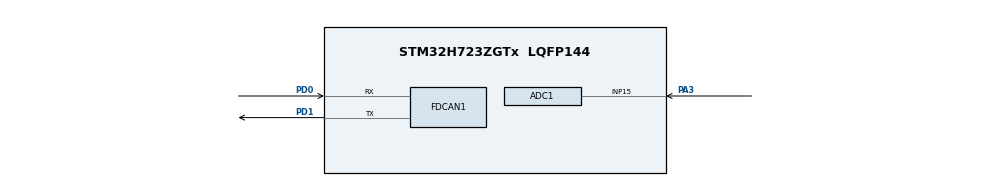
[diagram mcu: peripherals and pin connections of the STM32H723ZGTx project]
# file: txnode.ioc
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ADC1.Channel-0\#ChannelRegularConversion=ADC_CHANNEL_15
ADC1.ContinuousConvMode=DISABLE
ADC1.ConversionDataManagement=ADC_CONVERSIONDATA_DMA_CIRCULAR
ADC1.ExternalTrigConv=ADC_EXTERNALTRIG_T6_TRGO
ADC1.NbrOfConversionFlag=1
ADC1.OffsetNumber-0\#ChannelRegularConversion=ADC_OFFSET_NONE
ADC1.OffsetSignedSaturation-0\#ChannelRegularConversion=DISABLE
ADC1.Rank-0\#ChannelRegularConversion=1
ADC1.SamplingTime-0\#ChannelRegularConversion=ADC_SAMPLETIME_387CYCLES_5
ADC1.master=1
CORTEX_M7.default_mode_Activation=1
Dma.ADC1.0.Direction=DMA_PERIPH_TO_MEMORY
Dma.ADC1.0.EventEnable=DISABLE
Dma.ADC1.0.FIFOMode=DMA_FIFOMODE_DISABLE
Dma.ADC1.0.Instance=DMA1_Stream0
Dma.ADC1.0.MemDataAlignment=DMA_MDATAALIGN_HALFWORD
Dma.ADC1.0.MemInc=DMA_MINC_ENABLE
Dma.ADC1.0.Mode=DMA_CIRCULAR
Dma.ADC1.0.PeriphDataAlignment=DMA_PDATAALIGN_HALFWORD
Dma.ADC1.0.PeriphInc=DMA_PINC_DISABLE
Dma.ADC1.0.Polarity=HAL_DMAMUX_REQ_GEN_RISING
Dma.ADC1.0.Priority=DMA_PRIORITY_LOW
Dma.ADC1.0.RequestNumber=1
Dma.ADC1.0.SignalID=NONE
Dma.ADC1.0.SyncEnable=DISABLE
Dma.ADC1.0.SyncPolarity=HAL_DMAMUX_SYNC_NO_EVENT
Dma.ADC1.0.SyncRequestNumber=1
Dma.ADC1.0.SyncSignalID=NONE
Dma.Request0=ADC1
FDCAN1.AutoRetransmission=ENABLE
FDCAN1.CalculateBaudRateNominal=1000000
FDCAN1.CalculateTimeBitNominal=1000
FDCAN1.CalculateTimeQuantumNominal=62.5
FDCAN1.ClockCalibrationCCU=DISABLE
FDCAN1.DataSyncJumpWidth=6
FDCAN1.DataTimeSeg1=17
FDCAN1.DataTimeSeg2=6
FDCAN1.ExtFiltersNbr=0
FDCAN1.FrameFormat=FDCAN_FRAME_FD_BRS
FDCAN1.Mode=FDCAN_MODE_NORMAL
FDCAN1.NominalPrescaler=6
FDCAN1.NominalSyncJumpWidth=2
FDCAN1.NominalTimeSeg1=11
FDCAN1.NominalTimeSeg2=4
FDCAN1.RxBufferSize=FDCAN_DATA_BYTES_16
FDCAN1.RxFifo0ElmtSize=FDCAN_DATA_BYTES_16
FDCAN1.RxFifo0ElmtsNbr=8
FDCAN1.RxFifo1ElmtSize=FDCAN_DATA_BYTES_16
FDCAN1.RxFifo1ElmtsNbr=0
FDCAN1.StdFiltersNbr=1
FDCAN1.TxElmtSize=FDCAN_DATA_BYTES_16
FDCAN1.TxFifoQueueElmtsNbr=8
Mcu.Family=STM32H7
Mcu.Name=STM32H723ZGTx
Mcu.Package=LQFP144
NUCLEO-H723ZG.BUTTON=1
NUCLEO-H723ZG.LD1=true
NUCLEO-H723ZG.LD2=true
NUCLEO-H723ZG.LD3=true
NUCLEO-H723ZG.VCP=true
NVIC.DMA1_Stream0_IRQn=true\:0\:0\:false\:false\:true\:false\:true\:true
NVIC.EXTI15_10_IRQn=true\:0\:0\:false\:false\:true\:false\:true\:true
NVIC.PriorityGroup=NVIC_PRIORITYGROUP_4
PA13(JTMS/SWDIO).GPIO_Label=SWDIO
PA13(JTMS/SWDIO).Signal=DEBUG_JTMS-SWDIO
PA14(JTCK/SWCLK).GPIO_Label=SWCLK
PA14(JTCK/SWCLK).Signal=DEBUG_JTCK-SWCLK
PA3.Signal=ADCx_INP15
PC14-OSC32_IN.Signal=RCC_OSC32_IN
PC15-OSC32_OUT.Signal=RCC_OSC32_OUT
PD0.Mode=FDCAN_Activate
PD0.Signal=FDCAN1_RX
PD1.Mode=FDCAN_Activate
PD1.Signal=FDCAN1_TX
PD8.Signal=USART3_TX
PD9.Signal=USART3_RX
ProjectManager.HeapSize=0x200
ProjectManager.StackSize=0x400
ProjectManager.TargetToolchain=STM32CubeIDE
RCC.ADCFreq_Value=48000000
RCC.APB1Freq_Value=96000000
RCC.APB2Freq_Value=96000000
RCC.APB3Freq_Value=96000000
RCC.APB4Freq_Value=96000000
RCC.CortexFreq_Value=192000000
RCC.D1PPRE=RCC_APB3_DIV2
RCC.D2PPRE1=RCC_APB1_DIV2
RCC.D2PPRE2=RCC_APB2_DIV2
RCC.D3PPRE=RCC_APB4_DIV2
RCC.DIVM1=4
RCC.DIVM2=4
RCC.DIVN1=12
RCC.DIVN2=12
RCC.DIVP1=1
RCC.DIVP2=4
RCC.HCLKFreq_Value=192000000
RCC.HSE_VALUE=8000000
RCC.PLL2FRACN=0
RCC.PLLFRACN=0
RCC.SYSCLKFreq_VALUE=192000000
RCC.SYSCLKSource=RCC_SYSCLKSOURCE_PLLCLK
RCC.USBCLockSelection=RCC_USBCLKSOURCE_HSI48
RCC.USBFreq_Value=48000000
SH.ADCx_INP15.0=ADC1_INP15,IN15-Single-Ended
TIM6.Period=2-1
TIM6.Prescaler=12500-1
TIM6.TIM_MasterOutputTrigger=TIM_TRGO_UPDATE
VP_MEMORYMAP_VS_MEMORYMAP.Mode=CurAppReg
VP_NUCLEO-H723ZG_VS_BSP_COMMON.Mode=COMMON
VP_TIM6_VS_ClockSourceINT.Mode=Enable_Timer
board=NUCLEO-H723ZG

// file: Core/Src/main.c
/* USER CODE BEGIN Header */
/**
  ******************************************************************************
  * @file           : main.c
  * @brief          : Main program body
  ******************************************************************************
  * @attention
  *
  * Copyright (c) 2026 STMicroelectronics.
  * All rights reserved.
  *
  * This software is licensed under terms that can be found in the LICENSE file
  * in the root directory of this software component.
  * If no LICENSE file comes with this software, it is provided AS-IS.
  *
  ******************************************************************************
  */
/* USER CODE END Header */
#include "main.h"

COM_InitTypeDef BspCOMInit;
ADC_HandleTypeDef hadc1;
DMA_HandleTypeDef hdma_adc1;

FDCAN_HandleTypeDef hfdcan1;

TIM_HandleTypeDef htim6;

/* USER CODE BEGIN PV */
uint16_t ADCbuffer[16];
FDCAN_TxHeaderTypeDef txHeader;
volatile uint16_t decimation = 0;

/* USER CODE END PV */

void SystemClock_Config(void);
static void MPU_Config(void);
static void MX_GPIO_Init(void);
static void MX_DMA_Init(void);
static void MX_FDCAN1_Init(void);
static void MX_ADC1_Init(void);
static void MX_TIM6_Init(void);

/* USER CODE BEGIN 0 */
#include <stdio.h>
#include <string.h>
#include "stm32h7xx_nucleo.h"

extern UART_HandleTypeDef hcom_uart[COMn];
/* USER CODE END 0 */

int main(void)
{

  /* MPU Configuration--------------------------------------------------------*/
  MPU_Config();

  /* MCU Configuration--------------------------------------------------------*/

  /* Reset of all peripherals, Initializes the Flash interface and the Systick. */
  HAL_Init();

  /* Configure the system clock */
  SystemClock_Config();

  /* Initialize all configured peripherals */
  MX_GPIO_Init();
  MX_DMA_Init();
  MX_FDCAN1_Init();
  MX_ADC1_Init();
  MX_TIM6_Init();
  /* USER CODE BEGIN 2 */
  HAL_ADC_Start_DMA(&hadc1, (uint32_t*)&ADCbuffer, 16);
  HAL_TIM_Base_Start(&htim6);
 //uint8_t txData[16];
 //static uint8_t idx = 0;
 //static uint16_t samples[8];
 //static uint8_t adc_idx = 0;

  //FDCAN_ProtocolStatusTypeDef status;
  //uint32_t g_txFree;
  //uint32_t g_txcount;

  /* Start FDCAN */
  HAL_FDCAN_Start(&hfdcan1);

  /* Konfigurera TX frame */
  txHeader.Identifier = 0x102;
  txHeader.IdType = FDCAN_STANDARD_ID;
  txHeader.TxFrameType = FDCAN_DATA_FRAME;
  txHeader.DataLength = FDCAN_DLC_BYTES_16;
  txHeader.ErrorStateIndicator = FDCAN_ESI_ACTIVE;
  txHeader.BitRateSwitch = FDCAN_BRS_ON;
  txHeader.FDFormat = FDCAN_FD_CAN;
  txHeader.TxEventFifoControl = FDCAN_NO_TX_EVENTS;
  txHeader.MessageMarker = 0;

  /* USER CODE END 2 */

  /* Initialize leds */
  BSP_LED_Init(LED_GREEN);
  BSP_LED_Init(LED_YELLOW);
  BSP_LED_Init(LED_RED);

  /* Initialize USER push-button, will be used to trigger an interrupt each time it's pressed.*/
  BSP_PB_Init(BUTTON_USER, BUTTON_MODE_EXTI);

  /* Initialize COM1 port (115200, 8 bits (7-bit data + 1 stop bit), no parity */
  BspCOMInit.BaudRate   = 115200;
  BspCOMInit.WordLength = COM_WORDLENGTH_8B;
  BspCOMInit.StopBits   = COM_STOPBITS_1;
  BspCOMInit.Parity     = COM_PARITY_NONE;
  BspCOMInit.HwFlowCtl  = COM_HWCONTROL_NONE;
  if (BSP_COM_Init(COM1, &BspCOMInit) != BSP_ERROR_NONE)
  {
    Error_Handler();
  }

  /* Infinite loop */
  /* USER CODE BEGIN WHILE */

  while (1){}
  /*while (1)
  {
      // Läs nästa sample från DMA-buffer
      uint16_t value = ADCbuffer[adc_idx];
      adc_idx = (adc_idx + 1) % 16;

      // DEBUG (kan tas bort senare)
      //char msg[20];
      //sprintf(msg, "%u\r\n", value);
      //HAL_UART_Transmit(&hcom_uart[COM1], (uint8_t*)msg, strlen(msg), HAL_MAX_DELAY);

      // samla 4 samples
      samples[idx++] = value;

      if (idx == 8)
      {
          // packa till 8 bytes
          for (int i = 0; i < 8; i++)
          {
              txData[2*i]   = samples[i] >> 8;
              txData[2*i+1] = samples[i] & 0xFF;
          }

          // skicka CAN
          if (HAL_FDCAN_GetTxFifoFreeLevel(&hfdcan1) > 0)
          {
              HAL_FDCAN_AddMessageToTxFifoQ(&hfdcan1, &txHeader, txData);
          }

          idx = 0;
          HAL_Delay(250);
      }

      //HAL_Delay(250);
  }*/
    /* USER CODE END WHILE */

}

void SystemClock_Config(void)
{
  RCC_OscInitTypeDef RCC_OscInitStruct = {0};
  RCC_ClkInitTypeDef RCC_ClkInitStruct = {0};

  /** Supply configuration update enable
  */
  HAL_PWREx_ConfigSupply(PWR_LDO_SUPPLY);

  /** Configure the main internal regulator output voltage
  */
  __HAL_PWR_VOLTAGESCALING_CONFIG(PWR_REGULATOR_VOLTAGE_SCALE1);

  while(!__HAL_PWR_GET_FLAG(PWR_FLAG_VOSRDY)) {}

  /** Initializes the RCC Oscillators according to the specified parameters
  * in the RCC_OscInitTypeDef structure.
  */
  RCC_OscInitStruct.OscillatorType = RCC_OSCILLATORTYPE_HSI;
  RCC_OscInitStruct.HSIState = RCC_HSI_DIV1;
  RCC_OscInitStruct.HSICalibrationValue = 64;
  RCC_OscInitStruct.PLL.PLLState = RCC_PLL_ON;
  RCC_OscInitStruct.PLL.PLLSource = RCC_PLLSOURCE_HSI;
  RCC_OscInitStruct.PLL.PLLM = 4;
  RCC_OscInitStruct.PLL.PLLN = 12;
  RCC_OscInitStruct.PLL.PLLP = 1;
  RCC_OscInitStruct.PLL.PLLQ = 2;
  RCC_OscInitStruct.PLL.PLLR = 2;
  RCC_OscInitStruct.PLL.PLLRGE = RCC_PLL1VCIRANGE_3;
  RCC_OscInitStruct.PLL.PLLVCOSEL = RCC_PLL1VCOWIDE;
  RCC_OscInitStruct.PLL.PLLFRACN = 0;
  if (HAL_RCC_OscConfig(&RCC_OscInitStruct) != HAL_OK)
  {
    Error_Handler();
  }

  /** Initializes the CPU, AHB and APB buses clocks
  */
  RCC_ClkInitStruct.ClockType = RCC_CLOCKTYPE_HCLK|RCC_CLOCKTYPE_SYSCLK
                              |RCC_CLOCKTYPE_PCLK1|RCC_CLOCKTYPE_PCLK2
                              |RCC_CLOCKTYPE_D3PCLK1|RCC_CLOCKTYPE_D1PCLK1;
  RCC_ClkInitStruct.SYSCLKSource = RCC_SYSCLKSOURCE_PLLCLK;
  RCC_ClkInitStruct.SYSCLKDivider = RCC_SYSCLK_DIV1;
  RCC_ClkInitStruct.AHBCLKDivider = RCC_HCLK_DIV1;
  RCC_ClkInitStruct.APB3CLKDivider = RCC_APB3_DIV2;
  RCC_ClkInitStruct.APB1CLKDivider = RCC_APB1_DIV2;
  RCC_ClkInitStruct.APB2CLKDivider = RCC_APB2_DIV2;
  RCC_ClkInitStruct.APB4CLKDivider = RCC_APB4_DIV2;

  if (HAL_RCC_ClockConfig(&RCC_ClkInitStruct, FLASH_LATENCY_2) != HAL_OK)
  {
    Error_Handler();
  }
}

static void MX_ADC1_Init(void)
{

  ADC_MultiModeTypeDef multimode = {0};
  ADC_ChannelConfTypeDef sConfig = {0};

  /** Common config
  */
  hadc1.Instance = ADC1;
  hadc1.Init.ClockPrescaler = ADC_CLOCK_ASYNC_DIV1;
  hadc1.Init.Resolution = ADC_RESOLUTION_16B;
  hadc1.Init.ScanConvMode = ADC_SCAN_DISABLE;
  hadc1.Init.EOCSelection = ADC_EOC_SINGLE_CONV;
  hadc1.Init.LowPowerAutoWait = DISABLE;
  hadc1.Init.ContinuousConvMode = DISABLE;
  hadc1.Init.NbrOfConversion = 1;
  hadc1.Init.DiscontinuousConvMode = DISABLE;
  hadc1.Init.ExternalTrigConv = ADC_EXTERNALTRIG_T6_TRGO;
  hadc1.Init.ExternalTrigConvEdge = ADC_EXTERNALTRIGCONVEDGE_RISING;
  hadc1.Init.ConversionDataManagement = ADC_CONVERSIONDATA_DMA_CIRCULAR;
  hadc1.Init.Overrun = ADC_OVR_DATA_PRESERVED;
  hadc1.Init.LeftBitShift = ADC_LEFTBITSHIFT_NONE;
  hadc1.Init.OversamplingMode = DISABLE;
  hadc1.Init.Oversampling.Ratio = 1;
  if (HAL_ADC_Init(&hadc1) != HAL_OK)
  {
    Error_Handler();
  }
  HAL_Delay(1);
  HAL_ADCEx_Calibration_Start(&hadc1, ADC_CALIB_OFFSET, ADC_SINGLE_ENDED);

  /** Configure the ADC multi-mode
  */
  multimode.Mode = ADC_MODE_INDEPENDENT;
  if (HAL_ADCEx_MultiModeConfigChannel(&hadc1, &multimode) != HAL_OK)
  {
    Error_Handler();
  }

  /** Configure Regular Channel
  */
  sConfig.Channel = ADC_CHANNEL_15;
  sConfig.Rank = ADC_REGULAR_RANK_1;
  sConfig.SamplingTime = ADC_SAMPLETIME_387CYCLES_5;
  sConfig.SingleDiff = ADC_SINGLE_ENDED;
  sConfig.OffsetNumber = ADC_OFFSET_NONE;
  sConfig.Offset = 0;
  sConfig.OffsetSignedSaturation = DISABLE;
  if (HAL_ADC_ConfigChannel(&hadc1, &sConfig) != HAL_OK)
  {
    Error_Handler();
  }

}

static void MX_FDCAN1_Init(void)
{

  hfdcan1.Instance = FDCAN1;
  hfdcan1.Init.FrameFormat = FDCAN_FRAME_FD_BRS;
  hfdcan1.Init.Mode = FDCAN_MODE_NORMAL;
  hfdcan1.Init.AutoRetransmission = ENABLE;
  hfdcan1.Init.TransmitPause = DISABLE;
  hfdcan1.Init.ProtocolException = DISABLE;
  hfdcan1.Init.NominalPrescaler = 6;
  hfdcan1.Init.NominalSyncJumpWidth = 2;
  hfdcan1.Init.NominalTimeSeg1 = 11;
  hfdcan1.Init.NominalTimeSeg2 = 4;
  hfdcan1.Init.DataPrescaler = 1;
  hfdcan1.Init.DataSyncJumpWidth = 6;
  hfdcan1.Init.DataTimeSeg1 = 17;
  hfdcan1.Init.DataTimeSeg2 = 6;
  hfdcan1.Init.MessageRAMOffset = 0;
  hfdcan1.Init.StdFiltersNbr = 1;
  hfdcan1.Init.ExtFiltersNbr = 0;
  hfdcan1.Init.RxFifo0ElmtsNbr = 8;
  hfdcan1.Init.RxFifo0ElmtSize = FDCAN_DATA_BYTES_16;
  hfdcan1.Init.RxFifo1ElmtsNbr = 0;
  hfdcan1.Init.RxFifo1ElmtSize = FDCAN_DATA_BYTES_16;
  hfdcan1.Init.RxBuffersNbr = 0;
  hfdcan1.Init.RxBufferSize = FDCAN_DATA_BYTES_16;
  hfdcan1.Init.TxEventsNbr = 0;
  hfdcan1.Init.TxBuffersNbr = 0;
  hfdcan1.Init.TxFifoQueueElmtsNbr = 8;
  hfdcan1.Init.TxFifoQueueMode = FDCAN_TX_FIFO_OPERATION;
  hfdcan1.Init.TxElmtSize = FDCAN_DATA_BYTES_16;
  if (HAL_FDCAN_Init(&hfdcan1) != HAL_OK)
  {
    Error_Handler();
  }

}

static void MX_TIM6_Init(void)
{

  TIM_MasterConfigTypeDef sMasterConfig = {0};

  htim6.Instance = TIM6;
  htim6.Init.Prescaler = 12500-1;
  htim6.Init.CounterMode = TIM_COUNTERMODE_UP;
  htim6.Init.Period = 2-1;
  htim6.Init.AutoReloadPreload = TIM_AUTORELOAD_PRELOAD_DISABLE;
  if (HAL_TIM_Base_Init(&htim6) != HAL_OK)
  {
    Error_Handler();
  }
  sMasterConfig.MasterOutputTrigger = TIM_TRGO_UPDATE;
  sMasterConfig.MasterSlaveMode = TIM_MASTERSLAVEMODE_DISABLE;
  if (HAL_TIMEx_MasterConfigSynchronization(&htim6, &sMasterConfig) != HAL_OK)
  {
    Error_Handler();
  }

}

static void MX_DMA_Init(void)
{

  /* DMA controller clock enable */
  __HAL_RCC_DMA1_CLK_ENABLE();

  /* DMA interrupt init */
  /* DMA1_Stream0_IRQn interrupt configuration */
  HAL_NVIC_SetPriority(DMA1_Stream0_IRQn, 0, 0);
  HAL_NVIC_EnableIRQ(DMA1_Stream0_IRQn);

}

static void MX_GPIO_Init(void)
{

  /* GPIO Ports Clock Enable */
  __HAL_RCC_GPIOC_CLK_ENABLE();
  __HAL_RCC_GPIOA_CLK_ENABLE();
  __HAL_RCC_GPIOD_CLK_ENABLE();

}

/* USER CODE BEGIN 4 */
void process_and_send(uint16_t *data)
{
    uint8_t txData[16];

    for (int i = 0; i < 8; i++)
    {
        txData[2*i]   = data[i] >> 8;
        txData[2*i+1] = data[i] & 0xFF;
    }

    if (HAL_FDCAN_GetTxFifoFreeLevel(&hfdcan1) > 0)
    {
        HAL_FDCAN_AddMessageToTxFifoQ(&hfdcan1, &txHeader, txData);
    }
}
void HAL_ADC_ConvHalfCpltCallback(ADC_HandleTypeDef* hadc)
{
    process_and_send(&ADCbuffer[0]);   // första 8 samples
}

void HAL_ADC_ConvCpltCallback(ADC_HandleTypeDef* hadc)
{
    process_and_send(&ADCbuffer[8]);   // nästa 8 samples
}

/* USER CODE END 4 */

 /* MPU Configuration */

void MPU_Config(void)
{
  MPU_Region_InitTypeDef MPU_InitStruct = {0};

  /* Disables the MPU */
  HAL_MPU_Disable();

  /** Initializes and configures the Region and the memory to be protected
  */
  MPU_InitStruct.Enable = MPU_REGION_ENABLE;
  MPU_InitStruct.Number = MPU_REGION_NUMBER0;
  MPU_InitStruct.BaseAddress = 0x0;
  MPU_InitStruct.Size = MPU_REGION_SIZE_4GB;
  MPU_InitStruct.SubRegionDisable = 0x87;
  MPU_InitStruct.TypeExtField = MPU_TEX_LEVEL0;
  MPU_InitStruct.AccessPermission = MPU_REGION_NO_ACCESS;
  MPU_InitStruct.DisableExec = MPU_INSTRUCTION_ACCESS_DISABLE;
  MPU_InitStruct.IsShareable = MPU_ACCESS_SHAREABLE;
  MPU_InitStruct.IsCacheable = MPU_ACCESS_NOT_CACHEABLE;
  MPU_InitStruct.IsBufferable = MPU_ACCESS_NOT_BUFFERABLE;

  HAL_MPU_ConfigRegion(&MPU_InitStruct);
  /* Enables the MPU */
  HAL_MPU_Enable(MPU_PRIVILEGED_DEFAULT);

}

void Error_Handler(void)
{
  __disable_irq();
  while (1)
  {
  }
}
